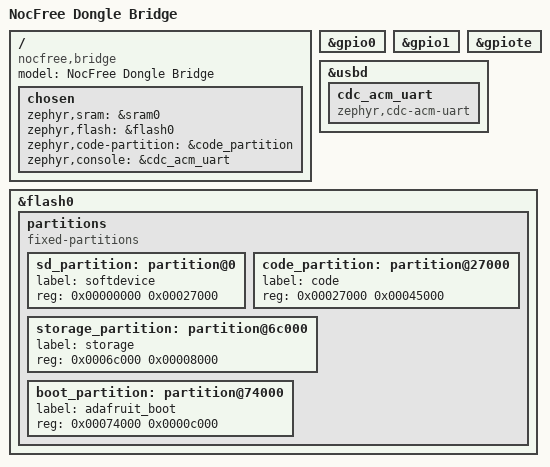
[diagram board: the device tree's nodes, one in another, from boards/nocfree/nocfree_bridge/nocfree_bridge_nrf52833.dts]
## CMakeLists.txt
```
# NocFree dongle BLE->USB HID bridge (standalone Zephyr app).
# NOT the leftover ZMK nocfree_dongle split-central board.
#
# Build (inside zmk-build-arm container):
#   bash /workspace/tools/inner_build_dongle_bridge_trial.sh
#
# Flash is intentionally NOT automated. See docs/DONGLE_SAFETY.md.

cmake_minimum_required(VERSION 3.20.0)

# Board lives next to this app so we never pull ZMK dongle Kconfig defaults.
list(APPEND BOARD_ROOT ${CMAKE_CURRENT_SOURCE_DIR})

find_package(Zephyr REQUIRED HINTS $ENV{ZEPHYR_BASE})
project(nocfree_dongle_bridge)

target_sources(app PRIVATE
  src/main.c
  src/recovery.c
  src/trial_autodfu.c
  src/usb_hid_bridge.c
  src/ble_hog_central.c
)

zephyr_library_include_directories(include)

# Hard refuse builds without USB recovery (dongle has no buttons / pinhole).
if(NOT CONFIG_NOCFREE_USB_RECOVERY)
  message(FATAL_ERROR
    "CONFIG_NOCFREE_USB_RECOVERY must be y. The dongle has no keys and no "
    "reset pinhole; refusing to build an unrecoverable image.")
endif()

# Trial = autodfu dead-man. Keeper = explicit opt-in, no autodfu.
# Bare prj.conf with neither is refused so nothing flashable is accidental.
if(CONFIG_NOCFREE_TRIAL_AUTODFU AND CONFIG_NOCFREE_BRIDGE_KEEPER)
  message(FATAL_ERROR
    "TRIAL autodfu and BRIDGE_KEEPER both set — refuse (contradictory).")
endif()
if(NOT CONFIG_NOCFREE_TRIAL_AUTODFU AND NOT CONFIG_NOCFREE_BRIDGE_KEEPER)
  message(FATAL_ERROR
    "Dongle bridge builds must be either TRIAL (prj_trial.conf) or KEEPER "
    "(prj_keeper.conf). Bare prj.conf alone is not flashable. "
    "See docs/DONGLE_SAFETY.md.")
endif()

if(CONFIG_LOG_MODE_IMMEDIATE AND CONFIG_LOG_BACKEND_UART)
  message(FATAL_ERROR
    "LOG_MODE_IMMEDIATE + LOG_BACKEND_UART is the 2026-08-09 brick combo. "
    "Refuse on dongle too.")
endif()
```

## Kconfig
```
# Application Kconfig for the dongle bridge.
# Sourced as the Zephyr app Kconfig via CMake (standard Zephyr layout).

mainmenu "NocFree Dongle Bridge"

config NOCFREE_USB_RECOVERY
	bool "1200-baud USB touch reboots into the UF2 bootloader"
	default y
	depends on USB_CDC_ACM
	select REBOOT
	select UART_LINE_CTRL
	help
	  ONLY software path into the bootloader on this device. Do not disable.

config NOCFREE_USB_RECOVERY_BAUD
	int "Baud rate that triggers recovery"
	default 1200
	depends on NOCFREE_USB_RECOVERY

config NOCFREE_USB_RECOVERY_POLL_MS
	int "CDC line-state poll period, ms"
	default 15
	depends on NOCFREE_USB_RECOVERY

config NOCFREE_BRIDGE_KEEPER
	bool "Permanent bridge image (no trial autodfu)"
	default n
	help
	  Opt-in for non-trial builds. Must keep USB recovery. Never enable
	  together with NOCFREE_TRIAL_AUTODFU.

config NOCFREE_TRIAL_AUTODFU
	bool "TRIAL ONLY: self-return to UF2 bootloader after a delay"
	default n
	depends on !NOCFREE_BRIDGE_KEEPER
	select REBOOT
	help
	  Dead-man for first flashes. NEVER ship as a permanent image.

config NOCFREE_TRIAL_AUTODFU_SECONDS
	int "Seconds before trial returns to bootloader"
	default 120
	depends on NOCFREE_TRIAL_AUTODFU

config NOCFREE_TRIAL_AUTODFU_WDT_SECONDS
	int "PRE_KERNEL_1 watchdog backstop, seconds"
	default 180
	depends on NOCFREE_TRIAL_AUTODFU

config NOCFREE_BRIDGE_BLE_ENABLE
	bool "Start BLE central HOG client (scan/connect stubs → full later)"
	default y
	depends on BT_CENTRAL

config NOCFREE_BRIDGE_USB_HID_ENABLE
	bool "Start USB HID keyboard/consumer device"
	default y
	depends on USB_DEVICE_HID

source "Kconfig.zephyr"
```

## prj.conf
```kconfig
# Dongle bridge base config. RC LFCLK only (crystal unverified on dongle).
# Keepers are LIVE since 2026-08-10 (prj_keeper.conf); NEW bridge code still
# goes through the trial ladder first (prj_trial.conf) per DONGLE_SAFETY.md.

CONFIG_MAIN_STACK_SIZE=4096
CONFIG_SYSTEM_WORKQUEUE_STACK_SIZE=4096
CONFIG_HEAP_MEM_POOL_SIZE=16384
CONFIG_BT_RX_STACK_SIZE=2048
CONFIG_BT_HCI_TX_STACK_SIZE=1536

# --- Clock: RC until crystal proven on THIS PCB ---
CONFIG_CLOCK_CONTROL_NRF=y
CONFIG_CLOCK_CONTROL_NRF_K32SRC_RC=y
CONFIG_CLOCK_CONTROL_NRF_K32SRC_500PPM=y
# CONFIG_CLOCK_CONTROL_NRF_K32SRC_XTAL is not set

CONFIG_GPIO=y
CONFIG_PINCTRL=y
CONFIG_SERIAL=y
CONFIG_CONSOLE=y
CONFIG_UART_CONSOLE=y
CONFIG_UART_LINE_CTRL=y
CONFIG_PRINTK=y
CONFIG_REBOOT=y

# --- USB: CDC recovery + HID (classic stack, matches recovery.c) ---
CONFIG_USB_DEVICE_STACK=y
CONFIG_USB_DEVICE_PRODUCT="NocFree Bridge"
CONFIG_USB_DEVICE_MANUFACTURER="NocFree"
CONFIG_USB_DEVICE_VID=0x2886
CONFIG_USB_DEVICE_PID=0x9029
CONFIG_USB_CDC_ACM=y
CONFIG_USB_DEVICE_HID=y
CONFIG_USB_HID_DEVICE_COUNT=1
CONFIG_USB_DEVICE_INITIALIZE_AT_BOOT=n

# --- BLE central (HOG client path; stubs first) ---
CONFIG_BT=y
CONFIG_BT_CENTRAL=y
CONFIG_BT_OBSERVER=y
CONFIG_BT_SMP=y
CONFIG_BT_GATT_CLIENT=y
CONFIG_BT_KEYS_OVERWRITE_OLDEST=y
CONFIG_BT_BONDABLE=y
CONFIG_BT_MAX_CONN=2
CONFIG_BT_MAX_PAIRED=2
# OFF: as central we set conn params explicitly at create and enforce them in
# le_param_req (ble_hog_central.c host_link_param pin); the GAP auto-updater
# would fight the pin. (The old comment here described the opposite setting.)
CONFIG_BT_GAP_AUTO_UPDATE_CONN_PARAMS=n
CONFIG_BT_DEVICE_NAME="NocFree Bridge"
CONFIG_BT_PRIVACY=n
CONFIG_BT_SETTINGS=y
CONFIG_BT_GATT_AUTO_DISCOVER_CCC=n
CONFIG_BT_CTLR=y
CONFIG_BT_LL_SW_SPLIT=y
# Match left half Windows interop preference
CONFIG_BT_CTLR_PHY_2M=n
CONFIG_BT_SMP_SC_PAIR_ONLY=y
# Just Works OK for keyboard↔dongle (no display)
# CONFIG_BT_SMP_ENFORCE_MITM is not set
# Allow re-pair when left already has an older unauth bond for this identity
CONFIG_BT_SMP_ALLOW_UNAUTH_OVERWRITE=y
CONFIG_SETTINGS=y
CONFIG_SETTINGS_NVS=y
CONFIG_NVS=y
CONFIG_FLASH=y
CONFIG_FLASH_MAP=y
CONFIG_FLASH_PAGE_LAYOUT=y

# UF2 / code partition (GPREGRET written in software; no retention DTS)
CONFIG_BUILD_OUTPUT_UF2=y
CONFIG_USE_DT_CODE_PARTITION=y

# Recovery seatbelt (app Kconfig defaults y; restate for clarity)
CONFIG_NOCFREE_USB_RECOVERY=y

# Trial/keeper flags live in prj_trial.conf / prj_keeper.conf only. Bare
# prj.conf alone fails the CMake gate (must be trial XOR keeper).
```

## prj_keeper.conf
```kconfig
# Permanent dongle bridge keeper. NO autodfu / NO trial WDT.
# Requires USB recovery (in prj.conf). Flash only with stock retreat ready.
# See docs/DONGLE_SAFETY.md.

CONFIG_NOCFREE_BRIDGE_KEEPER=y
# CONFIG_NOCFREE_TRIAL_AUTODFU is not set
```

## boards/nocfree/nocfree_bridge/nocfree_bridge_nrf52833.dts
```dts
/dts-v1/;
#include <nordic/nrf52833_qiaa.dtsi>

/*
 * NocFree & dongle — bridge board (no keys, no expanders).
 * Flash layout MUST match stock UF2 entry 0x27000 and Adafruit bootloader
 * at top of 512 KB. Wrong offsets can erase the bootloader = brick.
 *
 * Bootloader entry: recovery.c / trial_autodfu.c write GPREGRET=0x57 directly
 * (same as stock/ZMK). No ZMK boot-mode mapper DTS required.
 */

/ {
	model = "NocFree Dongle Bridge";
	compatible = "nocfree,bridge";

	chosen {
		zephyr,sram = &sram0;
		zephyr,flash = &flash0;
		zephyr,code-partition = &code_partition;
		zephyr,console = &cdc_acm_uart;
		/* zephyr,bt-hci comes from nrf52833.dtsi (&bt_hci_controller) */
	};
};

&gpio0 { status = "okay"; };
&gpio1 { status = "okay"; };

&gpiote {
	status = "okay";
};

&usbd {
	status = "okay";
	cdc_acm_uart: cdc_acm_uart {
		compatible = "zephyr,cdc-acm-uart";
	};
};

/* Same Adafruit layout as halves/stock dongle — do not invent partitions. */
&flash0 {
	partitions {
		compatible = "fixed-partitions";
		#address-cells = <1>;
		#size-cells = <1>;

		sd_partition: partition@0 {
			label = "softdevice";
			reg = <0x00000000 0x00027000>;
		};

		code_partition: partition@27000 {
			label = "code";
			reg = <0x00027000 0x00045000>;
		};

		storage_partition: partition@6c000 {
			label = "storage";
			reg = <0x0006c000 0x00008000>;
		};

		boot_partition: partition@74000 {
			label = "adafruit_boot";
			reg = <0x00074000 0x0000c000>;
		};
	};
};
```

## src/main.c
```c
/*
 * NocFree dongle bridge — phase 3 (HOG → USB HID).
 *
 * Flash ONLY as trial (autodfu+WDT). See docs/DONGLE_SAFETY.md.
 *
 * Test: left half on Bluetooth (or 2.4G profile the dongle bonds to),
 * advertising "NocFree &". Dongle USB into PC → type on keyboard.
 */

#include <zephyr/kernel.h>
#include <zephyr/sys/printk.h>
#include <zephyr/usb/usb_device.h>

#include "bridge.h"

int main(void)
{
	int err;

	printk("bridge: NocFree dongle bridge HOG client\n");
#if IS_ENABLED(CONFIG_NOCFREE_TRIAL_AUTODFU)
	printk("bridge: PID 0x9029 — TRIAL autodfu active\n");
#elif IS_ENABLED(CONFIG_NOCFREE_BRIDGE_KEEPER)
	printk("bridge: PID 0x9029 — KEEPER (no autodfu; recovery armed)\n");
#else
	printk("bridge: PID 0x9029\n");
#endif

	/*
	 * Register HID *before* usb_enable so the composite descriptor includes
	 * the keyboard interface. Enabling first then registering can leave
	 * Windows with a silent HID (no int_in_ready → all reports dropped).
	 */
#if IS_ENABLED(CONFIG_NOCFREE_BRIDGE_USB_HID_ENABLE)
	err = bridge_usb_hid_init();
	if (err) {
		printk("bridge: USB HID init failed: %d\n", err);
	}
#endif

	err = usb_enable(NULL);
	if (err && err != -EALREADY) {
		printk("bridge: usb_enable failed: %d\n", err);
	} else {
		printk("bridge: USB enabled (CDC recovery + HID)\n");
	}

#if IS_ENABLED(CONFIG_NOCFREE_BRIDGE_BLE_ENABLE)
	err = bridge_ble_init();
	if (err) {
		printk("bridge: BLE init failed: %d\n", err);
	}
#endif

	while (1) {
		k_sleep(K_SECONDS(30));
#if IS_ENABLED(CONFIG_NOCFREE_BRIDGE_USB_HID_ENABLE)
		{
			uint32_t ok = 0, drops = 0;
			uint8_t q = 0;

			bridge_usb_hid_stats(&ok, &drops, &q);
#if IS_ENABLED(CONFIG_NOCFREE_TRIAL_AUTODFU)
			printk("bridge: alive trial ok=%u drops=%u q=%u\n", ok, drops, q);
#else
			printk("bridge: alive ok=%u drops=%u q=%u\n", ok, drops, q);
#endif
		}
#else
		printk("bridge: alive\n");
#endif
	}

	return 0;
}
```

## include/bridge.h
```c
#pragma once

#include <zephyr/kernel.h>

/** USB HID keyboard + consumer device. */
int bridge_usb_hid_init(void);

/** BLE central: enable stack, start scanning for "NocFree &". */
int bridge_ble_init(void);

/** Forward an 8-byte boot keyboard report to USB (mods+rsvd+6 keys). Queued. */
int bridge_usb_hid_send_keyboard(const uint8_t *report8);

/**
 * Forward a 12-byte consumer report body (6 x uint16 LE usages, ZMK FULL).
 * Report ID 2 is prepended on the USB wire.
 */
int bridge_usb_hid_send_consumer(const uint8_t *report12);

/** Send all-keys-up on keyboard + empty consumer (stuck-key guard). */
int bridge_usb_hid_release_all(void);

/** Optional stats for diagnostics (ok TX, queue overflows, current depth). */
void bridge_usb_hid_stats(uint32_t *ok, uint32_t *drops, uint8_t *queued);
```

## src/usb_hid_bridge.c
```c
/*
 * USB HID face for the bridge (classic Zephyr USB HID class).
 * Queues keyboard + consumer reports so BLE notifies are not dropped when
 * the IN endpoint is busy (-EAGAIN).
 *
 * Wire format matches ZMK HOG on the left half:
 *   Report ID 1 — boot keyboard (8-byte body)
 *   Report ID 2 — consumer FULL (6 x uint16 usages)
 */

#include <string.h>

#include <zephyr/kernel.h>
#include <zephyr/spinlock.h>
#include <zephyr/sys/atomic.h>
#include <zephyr/sys/printk.h>
#include <zephyr/usb/usb_device.h>
#include <zephyr/usb/class/usb_hid.h>

#include "bridge.h"

#define KB_REPORT_SIZE 8
#define CONS_REPORT_SIZE 12 /* 6 x uint16 */
#define HID_Q_DEPTH 48
#define HID_BODY_MAX CONS_REPORT_SIZE

enum hid_rpt_kind {
	HID_RPT_KB = 1,
	HID_RPT_CONS = 2,
};

struct hid_q_item {
	uint8_t kind; /* HID_RPT_KB or HID_RPT_CONS */
	uint8_t len;
	uint8_t body[HID_BODY_MAX];
};

static const struct device *hid_dev;

static struct hid_q_item hid_q[HID_Q_DEPTH];
static uint8_t hid_q_head; /* next write */
static uint8_t hid_q_tail; /* next read */
static uint8_t hid_q_count;
static struct k_spinlock hid_q_lock;
static atomic_t hid_q_drops;
static atomic_t hid_tx_ok;

/*
 * HID report map: keyboard (ID 1) + consumer control FULL (ID 2).
 * Consumer layout matches CONFIG_ZMK_HID_CONSUMER_REPORT_USAGES_FULL on the
 * left half (6 array usages, 16-bit each).
 */
static const uint8_t hid_report_desc[] = {
	/* ---- Keyboard (Report ID 1) ---- */
	0x05, 0x01, /* Usage Page (Generic Desktop) */
	0x09, 0x06, /* Usage (Keyboard) */
	0xA1, 0x01, /* Collection (Application) */
	0x85, 0x01, /*   Report ID (1) */
	0x05, 0x07, /*   Usage Page (Key Codes) */
	0x19, 0xE0, /*   Usage Minimum (224) */
	0x29, 0xE7, /*   Usage Maximum (231) */
	0x15, 0x00, /*   Logical Minimum (0) */
	0x25, 0x01, /*   Logical Maximum (1) */
	0x75, 0x01, /*   Report Size (1) */
	0x95, 0x08, /*   Report Count (8) */
	0x81, 0x02, /*   Input (Data,Var,Abs) — modifiers */
	0x95, 0x01, /*   Report Count (1) */
	0x75, 0x08, /*   Report Size (8) */
	0x81, 0x01, /*   Input (Const) — reserved */
	0x95, 0x06, /*   Report Count (6) */
	0x75, 0x08, /*   Report Size (8) */
	0x15, 0x00, /*   Logical Minimum (0) */
	0x25, 0x65, /*   Logical Maximum (101) */
	0x05, 0x07, /*   Usage Page (Key Codes) */
	0x19, 0x00, /*   Usage Minimum (0) */
	0x29, 0x65, /*   Usage Maximum (101) */
	0x81, 0x00, /*   Input (Data,Array) — key array */
	0xC0,       /* End Collection */

	/* ---- Consumer Control FULL (Report ID 2) ---- */
	0x05, 0x0C,       /* Usage Page (Consumer) */
	0x09, 0x01,       /* Usage (Consumer Control) */
	0xA1, 0x01,       /* Collection (Application) */
	0x85, 0x02,       /*   Report ID (2) */
	0x15, 0x00,       /*   Logical Minimum (0) */
	0x26, 0xFF, 0xFF, /*   Logical Maximum (65535) */
	0x19, 0x00,       /*   Usage Minimum (0) */
	0x2A, 0xFF, 0xFF, /*   Usage Maximum (65535) */
	0x75, 0x10,       /*   Report Size (16) */
	0x95, 0x06,       /*   Report Count (6) */
	0x81, 0x00,       /*   Input (Data,Array,Abs) */
	0xC0,             /* End Collection */
};

static void hid_queue_push(uint8_t kind, const uint8_t *body, uint8_t len)
{
	k_spinlock_key_t key = k_spin_lock(&hid_q_lock);

	if (hid_q_count >= HID_Q_DEPTH) {
		/* Drop oldest, keep newest (prefer latest state for HOG). */
		hid_q_tail = (hid_q_tail + 1U) % HID_Q_DEPTH;
		hid_q_count--;
		atomic_inc(&hid_q_drops);
	}
	hid_q[hid_q_head].kind = kind;
	hid_q[hid_q_head].len = len;
	memcpy(hid_q[hid_q_head].body, body, len);
	if (len < HID_BODY_MAX) {
		memset(&hid_q[hid_q_head].body[len], 0, HID_BODY_MAX - len);
	}
	hid_q_head = (hid_q_head + 1U) % HID_Q_DEPTH;
	hid_q_count++;
	k_spin_unlock(&hid_q_lock, key);
}

static int hid_queue_peek_copy(struct hid_q_item *out)
{
	k_spinlock_key_t key = k_spin_lock(&hid_q_lock);

	if (hid_q_count == 0) {
		k_spin_unlock(&hid_q_lock, key);
		return -EAGAIN;
	}
	*out = hid_q[hid_q_tail];
	k_spin_unlock(&hid_q_lock, key);
	return 0;
}

static void hid_queue_pop(void)
{
	k_spinlock_key_t key = k_spin_lock(&hid_q_lock);

	if (hid_q_count > 0) {
		hid_q_tail = (hid_q_tail + 1U) % HID_Q_DEPTH;
		hid_q_count--;
	}
	k_spin_unlock(&hid_q_lock, key);
}

/*
 * Serialize the peek→write→pop cycle (2026-08-18 review). This function runs
 * from THREE thread contexts: BT RX (notify_func → send_*), the USB stack
 * thread (int_in_ready_cb) and the reconnect queue (release_all). The queue
 * spinlock makes each queue op atomic but not the SEQUENCE: two concurrent
 * drainers could peek the same item — duplicate send — and then both pop,
 * discarding a never-sent report behind it. HID reports are absolute state,
 * so a discarded report self-corrects on the next key event — but if it was
 * the final release of a burst, the host holds that key until the user types
 * again. K_NO_WAIT (never block the BT RX thread) + the post-unlock re-check:
 * a push that loses the lock race returns immediately, and the holder's
 * re-check picks the item up, so nothing is stranded until the next event.
 */
static K_MUTEX_DEFINE(hid_drain_lock);

static void hid_try_drain(void)
{
	struct hid_q_item item;
	uint8_t buf[1 + HID_BODY_MAX];
	int err;

	if (!hid_dev) {
		return;
	}

	while (true) {
		if (k_mutex_lock(&hid_drain_lock, K_NO_WAIT) != 0) {
			/* Someone is draining; their re-check covers our push. */
			return;
		}
		while (hid_queue_peek_copy(&item) == 0) {
			buf[0] = item.kind;
			memcpy(&buf[1], item.body, item.len);
			err = hid_int_ep_write(hid_dev, buf, (uint16_t)(1U + item.len), NULL);
			if (err == -EAGAIN) {
				/* Endpoint busy; int_in_ready will call us again. */
				k_mutex_unlock(&hid_drain_lock);
				return;
			}
			if (err) {
				printk("bridge/usb: hid write err %d (id=%u)\n", err, item.kind);
				/* Drop this report so we do not stall forever. */
				hid_queue_pop();
				continue;
			}
			hid_queue_pop();
			atomic_inc(&hid_tx_ok);
		}
		k_mutex_unlock(&hid_drain_lock);
		/* Re-check: a push between our last peek and the unlock lost the
		 * lock race and returned — drain again rather than strand it. */
		if (hid_queue_peek_copy(&item) != 0) {
			return;
		}
	}
}

static void int_in_ready_cb(const struct device *dev)
{
	ARG_UNUSED(dev);
	hid_try_drain();
}

static const struct hid_ops ops = {
	.int_in_ready = int_in_ready_cb,
};

int bridge_usb_hid_init(void)
{
	hid_dev = device_get_binding("HID_0");
	if (!hid_dev) {
		printk("bridge/usb: HID_0 not found\n");
		return -ENODEV;
	}

	usb_hid_register_device(hid_dev, hid_report_desc, sizeof(hid_report_desc),
				&ops);
	int err = usb_hid_init(hid_dev);
	if (err) {
		printk("bridge/usb: usb_hid_init failed: %d\n", err);
		return err;
	}

	printk("bridge/usb: HID kb+consumer registered (ID1/ID2, q=%u)\n", HID_Q_DEPTH);
	return 0;
}

int bridge_usb_hid_send_keyboard(const uint8_t *report8)
{
	if (!hid_dev || !report8) {
		return -ENODEV;
	}

	hid_queue_push(HID_RPT_KB, report8, KB_REPORT_SIZE);
	hid_try_drain();
	return 0;
}

int bridge_usb_hid_send_consumer(const uint8_t *report12)
{
	if (!hid_dev || !report12) {
		return -ENODEV;
	}

	hid_queue_push(HID_RPT_CONS, report12, CONS_REPORT_SIZE);
	hid_try_drain();
	return 0;
}

int bridge_usb_hid_release_all(void)
{
	static const uint8_t kb_zeros[KB_REPORT_SIZE];
	static const uint8_t cons_zeros[CONS_REPORT_SIZE];
	int err;

	err = bridge_usb_hid_send_keyboard(kb_zeros);
	(void)bridge_usb_hid_send_consumer(cons_zeros);
	return err;
}

void bridge_usb_hid_stats(uint32_t *ok, uint32_t *drops, uint8_t *queued)
{
	if (ok) {
		*ok = (uint32_t)atomic_get(&hid_tx_ok);
	}
	if (drops) {
		*drops = (uint32_t)atomic_get(&hid_q_drops);
	}
	if (queued) {
		k_spinlock_key_t key = k_spin_lock(&hid_q_lock);

		*queued = hid_q_count;
		k_spin_unlock(&hid_q_lock, key);
	}
}
```
